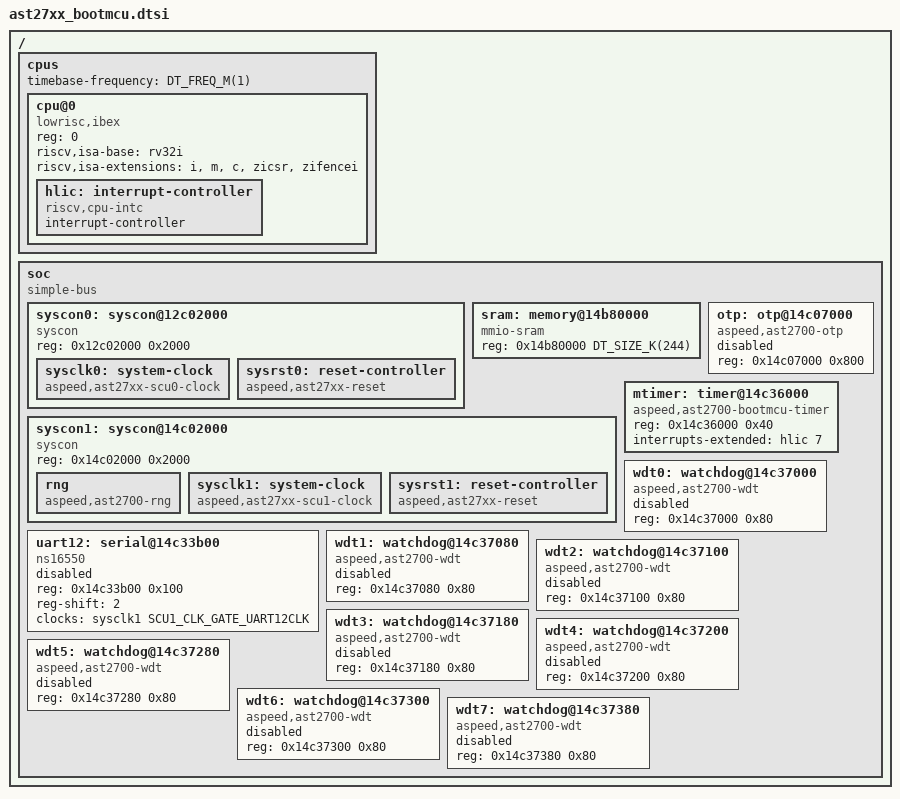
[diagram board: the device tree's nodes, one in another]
/*
 * Copyright (c) 2026 ASPEED Technology Inc.
 *
 * SPDX-License-Identifier: Apache-2.0
 */

#include <freq.h>
#include <mem.h>
#include <zephyr/dt-bindings/clock/ast27xx_clock.h>
#include <zephyr/dt-bindings/reset/ast27xx_reset.h>

/ {
	#address-cells = <1>;
	#size-cells = <1>;

	cpus {
		#address-cells = <1>;
		#size-cells = <0>;
		timebase-frequency = <DT_FREQ_M(1)>;

		cpu@0 {
			device_type = "cpu";
			compatible = "lowrisc,ibex", "riscv";
			reg = <0>;
			riscv,isa-base = "rv32i";
			riscv,isa-extensions = "i", "m", "c", "zicsr", "zifencei";

			hlic: interrupt-controller {
				compatible = "riscv,cpu-intc";
				#address-cells = <0>;
				#interrupt-cells = <1>;
				interrupt-controller;
			};
		};
	};

	soc {
		compatible = "simple-bus";
		#address-cells = <1>;
		#size-cells = <1>;
		ranges;

		syscon0: syscon@12c02000 {
			compatible = "syscon";
			reg = <0x12c02000 0x2000>;

			sysclk0: system-clock {
				compatible = "aspeed,ast27xx-scu0-clock";
				#clock-cells = <1>;
			};

			sysrst0: reset-controller {
				compatible = "aspeed,ast27xx-reset";
				#reset-cells = <1>;
			};
		};

		/* The boot ROM patch locks SRAM offsets 244 KB to 248 KB */
		sram: memory@14b80000 {
			compatible = "mmio-sram";
			reg = <0x14b80000 DT_SIZE_K(244)>;
		};

		syscon1: syscon@14c02000 {
			compatible = "syscon";
			reg = <0x14c02000 0x2000>;

			rng: rng {
				compatible = "aspeed,ast2700-rng";
			};

			sysclk1: system-clock {
				compatible = "aspeed,ast27xx-scu1-clock";
				#clock-cells = <1>;
			};

			sysrst1: reset-controller {
				compatible = "aspeed,ast27xx-reset";
				#reset-cells = <1>;
			};
		};

		otp: otp@14c07000 {
			compatible = "aspeed,ast2700-otp";
			reg = <0x14c07000 0x800>;
			status = "disabled";
		};

		uart12: serial@14c33b00 {
			compatible = "ns16550";
			reg = <0x14c33b00 0x100>;
			reg-shift = <2>;
			clocks = <&sysclk1 SCU1_CLK_GATE_UART12CLK>;
			status = "disabled";
		};

		mtimer: timer@14c36000 {
			compatible = "aspeed,ast2700-bootmcu-timer";
			reg = <0x14c36000 0x40>;
			interrupts-extended = <&hlic 7>;
		};

		wdt0: watchdog@14c37000 {
			compatible = "aspeed,ast2700-wdt";
			reg = <0x14c37000 0x80>;
			status = "disabled";
		};

		wdt1: watchdog@14c37080 {
			compatible = "aspeed,ast2700-wdt";
			reg = <0x14c37080 0x80>;
			status = "disabled";
		};

		wdt2: watchdog@14c37100 {
			compatible = "aspeed,ast2700-wdt";
			reg = <0x14c37100 0x80>;
			status = "disabled";
		};

		wdt3: watchdog@14c37180 {
			compatible = "aspeed,ast2700-wdt";
			reg = <0x14c37180 0x80>;
			status = "disabled";
		};

		wdt4: watchdog@14c37200 {
			compatible = "aspeed,ast2700-wdt";
			reg = <0x14c37200 0x80>;
			status = "disabled";
		};

		wdt5: watchdog@14c37280 {
			compatible = "aspeed,ast2700-wdt";
			reg = <0x14c37280 0x80>;
			status = "disabled";
		};

		wdt6: watchdog@14c37300 {
			compatible = "aspeed,ast2700-wdt";
			reg = <0x14c37300 0x80>;
			status = "disabled";
		};

		wdt7: watchdog@14c37380 {
			compatible = "aspeed,ast2700-wdt";
			reg = <0x14c37380 0x80>;
			status = "disabled";
		};
	};
};
